# PIC32MK1024GPL064 register map
Vendor: Microchip
Registers are 32-bit, read-write, no defined reset value unless marked. A register's access mark holds for its fields unless they carry their own. Addresses are absolute, and some are shared; only a register's first bit layout is shown; [hi:lo] are bit positions.

## SPI3
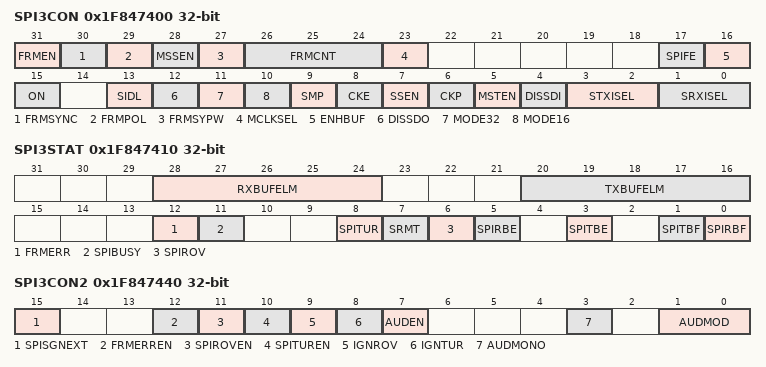
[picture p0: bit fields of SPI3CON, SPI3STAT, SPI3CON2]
0x1F847400 SPI3CON — (power-on value 00000000x-----0000000000000x0000)
  [31] FRMEN, [30] FRMSYNC, [29] FRMPOL, [28] MSSEN, [27] FRMSYPW, [26:24] FRMCNT, [23] MCLKSEL, [17] SPIFE, [16] ENHBUF, [15] ON, [13] SIDL, [12] DISSDO, [11] MODE32, [10] MODE16, [9] SMP, [8] CKE, [7] SSEN, [6] CKP, [5] MSTEN, [4] DISSDI, [3:2] STXISEL, [1:0] SRXISEL
0x1F847410 SPI3STAT — (power-on value ---00000---00000---x0--0000-0-00)
  [28:24] RXBUFELM ro, [20:16] TXBUFELM ro, [12] FRMERR, [11] SPIBUSY ro, [8] SPITUR ro, [7] SRMT ro, [6] SPIROV ro, [5] SPIRBE ro, [3] SPITBE ro, [1] SPITBF ro, [0] SPIRBF ro
0x1F847420 SPI3BUF — (power-on value xxxxxxxxxxxxxxxxxxxxxxxxxxxxxxxx)
0x1F847430 SPI3BRG — (power-on value -------------------xxxxxxxxxxxxx)
  [12:0] SPI3BRG
0x1F847440 SPI3CON2 — (power-on value ----------------x--xxxxxx---x-xx)
  [15] SPISGNEXT, [12] FRMERREN, [11] SPIROVEN, [10] SPITUREN, [9] IGNROV, [8] IGNTUR, [7] AUDEN, [3] AUDMONO, [1:0] AUDMOD

## SPI4
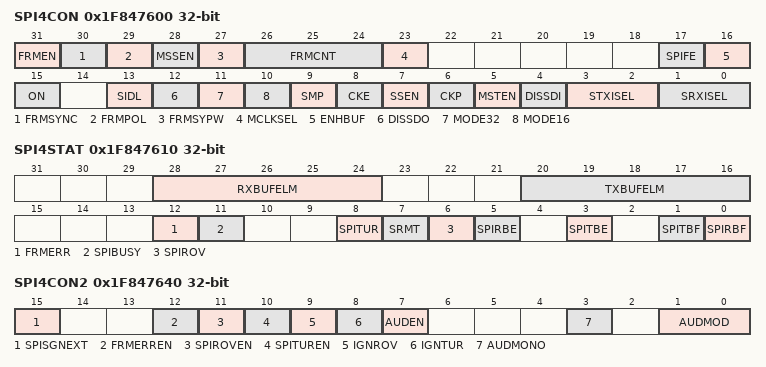
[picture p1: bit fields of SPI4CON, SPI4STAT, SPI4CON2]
0x1F847600 SPI4CON — (power-on value 00000000x-----0000000000000x0000)
  [31] FRMEN, [30] FRMSYNC, [29] FRMPOL, [28] MSSEN, [27] FRMSYPW, [26:24] FRMCNT, [23] MCLKSEL, [17] SPIFE, [16] ENHBUF, [15] ON, [13] SIDL, [12] DISSDO, [11] MODE32, [10] MODE16, [9] SMP, [8] CKE, [7] SSEN, [6] CKP, [5] MSTEN, [4] DISSDI, [3:2] STXISEL, [1:0] SRXISEL
0x1F847610 SPI4STAT — (power-on value ---00000---00000---x0--0000-0-00)
  [28:24] RXBUFELM ro, [20:16] TXBUFELM ro, [12] FRMERR, [11] SPIBUSY ro, [8] SPITUR ro, [7] SRMT ro, [6] SPIROV ro, [5] SPIRBE ro, [3] SPITBE ro, [1] SPITBF ro, [0] SPIRBF ro
0x1F847620 SPI4BUF — (power-on value xxxxxxxxxxxxxxxxxxxxxxxxxxxxxxxx)
0x1F847630 SPI4BRG — (power-on value -------------------xxxxxxxxxxxxx)
  [12:0] SPI4BRG
0x1F847640 SPI4CON2 — (power-on value ----------------x--xxxxxx---x-xx)
  [15] SPISGNEXT, [12] FRMERREN, [11] SPIROVEN, [10] SPITUREN, [9] IGNROV, [8] IGNTUR, [7] AUDEN, [3] AUDMONO, [1:0] AUDMOD

## SPI5
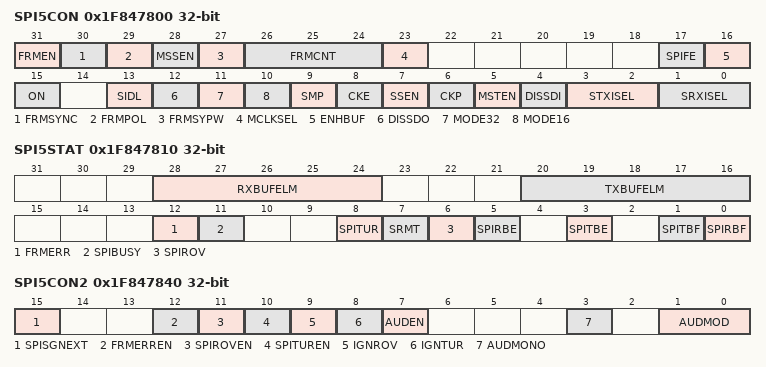
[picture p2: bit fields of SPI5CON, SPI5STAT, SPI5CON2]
0x1F847800 SPI5CON — (power-on value 00000000x-----0000000000000x0000)
  [31] FRMEN, [30] FRMSYNC, [29] FRMPOL, [28] MSSEN, [27] FRMSYPW, [26:24] FRMCNT, [23] MCLKSEL, [17] SPIFE, [16] ENHBUF, [15] ON, [13] SIDL, [12] DISSDO, [11] MODE32, [10] MODE16, [9] SMP, [8] CKE, [7] SSEN, [6] CKP, [5] MSTEN, [4] DISSDI, [3:2] STXISEL, [1:0] SRXISEL
0x1F847810 SPI5STAT — (power-on value ---00000---00000---x0--0000-0-00)
  [28:24] RXBUFELM ro, [20:16] TXBUFELM ro, [12] FRMERR, [11] SPIBUSY ro, [8] SPITUR ro, [7] SRMT ro, [6] SPIROV ro, [5] SPIRBE ro, [3] SPITBE ro, [1] SPITBF ro, [0] SPIRBF ro
0x1F847820 SPI5BUF — (power-on value xxxxxxxxxxxxxxxxxxxxxxxxxxxxxxxx)
0x1F847830 SPI5BRG — (power-on value -------------------xxxxxxxxxxxxx)
  [12:0] SPI5BRG
0x1F847840 SPI5CON2 — (power-on value ----------------x--xxxxxx---x-xx)
  [15] SPISGNEXT, [12] FRMERREN, [11] SPIROVEN, [10] SPITUREN, [9] IGNROV, [8] IGNTUR, [7] AUDEN, [3] AUDMONO, [1:0] AUDMOD

## SPI6
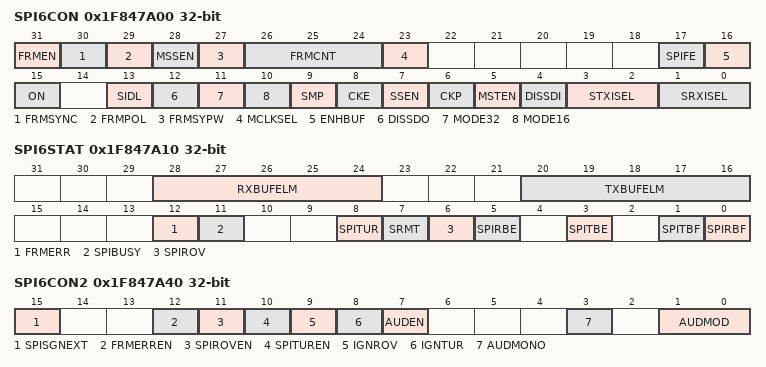
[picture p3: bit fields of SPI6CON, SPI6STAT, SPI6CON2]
0x1F847A00 SPI6CON — (power-on value 00000000x-----0000000000000x0000)
  [31] FRMEN, [30] FRMSYNC, [29] FRMPOL, [28] MSSEN, [27] FRMSYPW, [26:24] FRMCNT, [23] MCLKSEL, [17] SPIFE, [16] ENHBUF, [15] ON, [13] SIDL, [12] DISSDO, [11] MODE32, [10] MODE16, [9] SMP, [8] CKE, [7] SSEN, [6] CKP, [5] MSTEN, [4] DISSDI, [3:2] STXISEL, [1:0] SRXISEL
0x1F847A10 SPI6STAT — (power-on value ---00000---00000---x0--0000-0-00)
  [28:24] RXBUFELM ro, [20:16] TXBUFELM ro, [12] FRMERR, [11] SPIBUSY ro, [8] SPITUR ro, [7] SRMT ro, [6] SPIROV ro, [5] SPIRBE ro, [3] SPITBE ro, [1] SPITBF ro, [0] SPIRBF ro
0x1F847A20 SPI6BUF — (power-on value xxxxxxxxxxxxxxxxxxxxxxxxxxxxxxxx)
0x1F847A30 SPI6BRG — (power-on value -------------------xxxxxxxxxxxxx)
  [12:0] SPI6BRG
0x1F847A40 SPI6CON2 — (power-on value ----------------x--xxxxxx---x-xx)
  [15] SPISGNEXT, [12] FRMERREN, [11] SPIROVEN, [10] SPITUREN, [9] IGNROV, [8] IGNTUR, [7] AUDEN, [3] AUDMONO, [1:0] AUDMOD
